# STM32H7A3xxQ register map
File version: 1.0
Registers are 32-bit, read-write, reset 0x0 unless marked. A register's access mark holds for its fields unless they carry their own. Offsets are from the block's base; [hi:lo] are bit positions.

## COMP12 — Comparator
Base 0x58003800
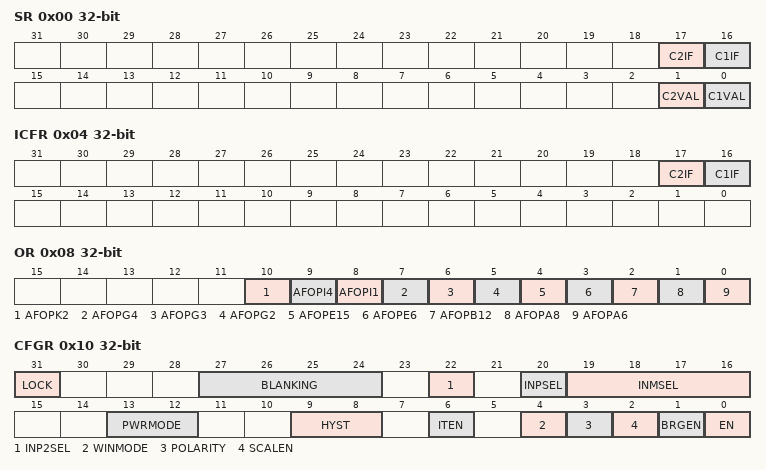
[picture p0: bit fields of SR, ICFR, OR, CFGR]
0x00 SR — Comparator status register
  [17] C2IF, [16] C1IF, [1] C2VAL, [0] C1VAL
0x04 ICFR — Comparator interrupt clear flag register
  [17] C2IF, [16] C1IF
0x08 OR — Comparator option register
  [10] AFOPK2, [9] AFOPI4, [8] AFOPI1, [7] AFOPG4, [6] AFOPG3, [5] AFOPG2, [4] AFOPE15, [3] AFOPE6, [2] AFOPB12, [1] AFOPA8, [0] AFOPA6
0x10 CFGR — COMP control and status register, used for bits common to several COMP instances
  [31] LOCK — COMPx Lock Bit
  [27:24] BLANKING — COMPx blanking source selection bits
    0=NONE (Comparator output without blanking); 1=TIM1_OC5 (Comparator output blanking source TIM1 OC5 (common to all COMP instances: COMP1, COMP2)); 2=TIM2_OC3 (Comparator output blanking source TIM2 OC3 (common to all COMP instances: COMP1, COMP2)); 3=TIM3_OC3 (Comparator output blanking source TIM3 OC3 (common to all COMP instances: COMP1, COMP2)); 4=TIM3_OC4 (Comparator output blanking source TIM3 OC4 (common to all COMP instances: COMP1, COMP2)); 5=TIM8_OC5 (Comparator output blanking source TIM8 OC5 (common to all COMP instances: COMP1, COMP2)); 6=TIM15_OC1 (Comparator output blanking source TIM15 OC1 (common to all COMP instances: COMP1, COMP2))
  [22] INP2SEL — COMPx input plus 2 selection bit
  [20] INPSEL — COMPx input plus selection bit
  [19:16] INMSEL — COMPx input minus selection bit
  [13:12] PWRMODE — COMPx Power Mode of the comparator
    0=HIGHSPEED (COMP power mode to high speed); 1=MEDIUMSPEED (COMP power mode to medium speed); 3=ULTRALOWPOWER (COMP power mode to ultra-low power)
  [9:8] HYST — COMPx hysteresis selection bits
    0=NONE (No hysteresis); 1=LOW (Hysteresis level low); 2=MEDIUM (Hysteresis level medium); 3=HIGH (Hysteresis level high)
  [6] ITEN — COMPx interrupt enable
  [4] WINMODE — COMPx Windows mode selection bit
    0=DISABLE (Window mode disable: Comparators 1 and 2 are independent); 1=COMP1_INPUT_PLUS_COMMON (Window mode enable: Comparators instances pair COMP1 and COMP2 have their input plus connected together. The common input is COMP1 input plus (COMP2 input plus is no more accessible).)
  [3] POLARITY — COMPx polarity selection bit
    0=NONINVERTED (COMP output polarity is not inverted: comparator output is high when the plus (non-inverting) input is at a higher voltage than the minus (inverting) input); 1=INVERTED (COMP output polarity is inverted: comparator output is low when the plus (non-inverting) input is at a lower voltage than the minus (inverting) input)
  [2] SCALEN — COMPx Voltage scaler enable bit
  [1] BRGEN — COMPx Scaler bridge enable
  [0] EN — COMPx enable bit

## COMP1
Base 0x5800380C
Same registers: COMP2 0x58003810
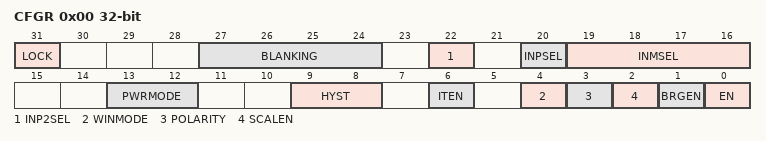
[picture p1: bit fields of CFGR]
0x00 CFGR — Comparator configuration register
  [31] LOCK — COMPx Lock Bit
  [27:24] BLANKING — COMPx blanking source selection bits
    0=NONE (Comparator output without blanking); 1=TIM1_OC5 (Comparator output blanking source TIM1 OC5 (common to all COMP instances: COMP1, COMP2)); 2=TIM2_OC3 (Comparator output blanking source TIM2 OC3 (common to all COMP instances: COMP1, COMP2)); 3=TIM3_OC3 (Comparator output blanking source TIM3 OC3 (common to all COMP instances: COMP1, COMP2)); 4=TIM3_OC4 (Comparator output blanking source TIM3 OC4 (common to all COMP instances: COMP1, COMP2)); 5=TIM8_OC5 (Comparator output blanking source TIM8 OC5 (common to all COMP instances: COMP1, COMP2)); 6=TIM15_OC1 (Comparator output blanking source TIM15 OC1 (common to all COMP instances: COMP1, COMP2))
  [22] INP2SEL — COMPx input plus 2 selection bit
  [20] INPSEL — COMPx input plus selection bit
  [19:16] INMSEL — COMPx input minus selection bit
  [13:12] PWRMODE — COMPx Power Mode of the comparator
    0=HIGHSPEED (COMP power mode to high speed); 1=MEDIUMSPEED (COMP power mode to medium speed); 3=ULTRALOWPOWER (COMP power mode to ultra-low power)
  [9:8] HYST — COMPx hysteresis selection bits
    0=NONE (No hysteresis); 1=LOW (Hysteresis level low); 2=MEDIUM (Hysteresis level medium); 3=HIGH (Hysteresis level high)
  [6] ITEN — COMPx interrupt enable
  [4] WINMODE — COMPx Windows mode selection bit
    0=DISABLE (Window mode disable: Comparators 1 and 2 are independent); 1=COMP1_INPUT_PLUS_COMMON (Window mode enable: Comparators instances pair COMP1 and COMP2 have their input plus connected together. The common input is COMP1 input plus (COMP2 input plus is no more accessible).)
  [3] POLARITY — COMPx polarity selection bit
    0=NONINVERTED (COMP output polarity is not inverted: comparator output is high when the plus (non-inverting) input is at a higher voltage than the minus (inverting) input); 1=INVERTED (COMP output polarity is inverted: comparator output is low when the plus (non-inverting) input is at a lower voltage than the minus (inverting) input)
  [2] SCALEN — COMPx Voltage scaler enable bit
  [1] BRGEN — COMPx Scaler bridge enable
  [0] EN — COMPx enable bit
